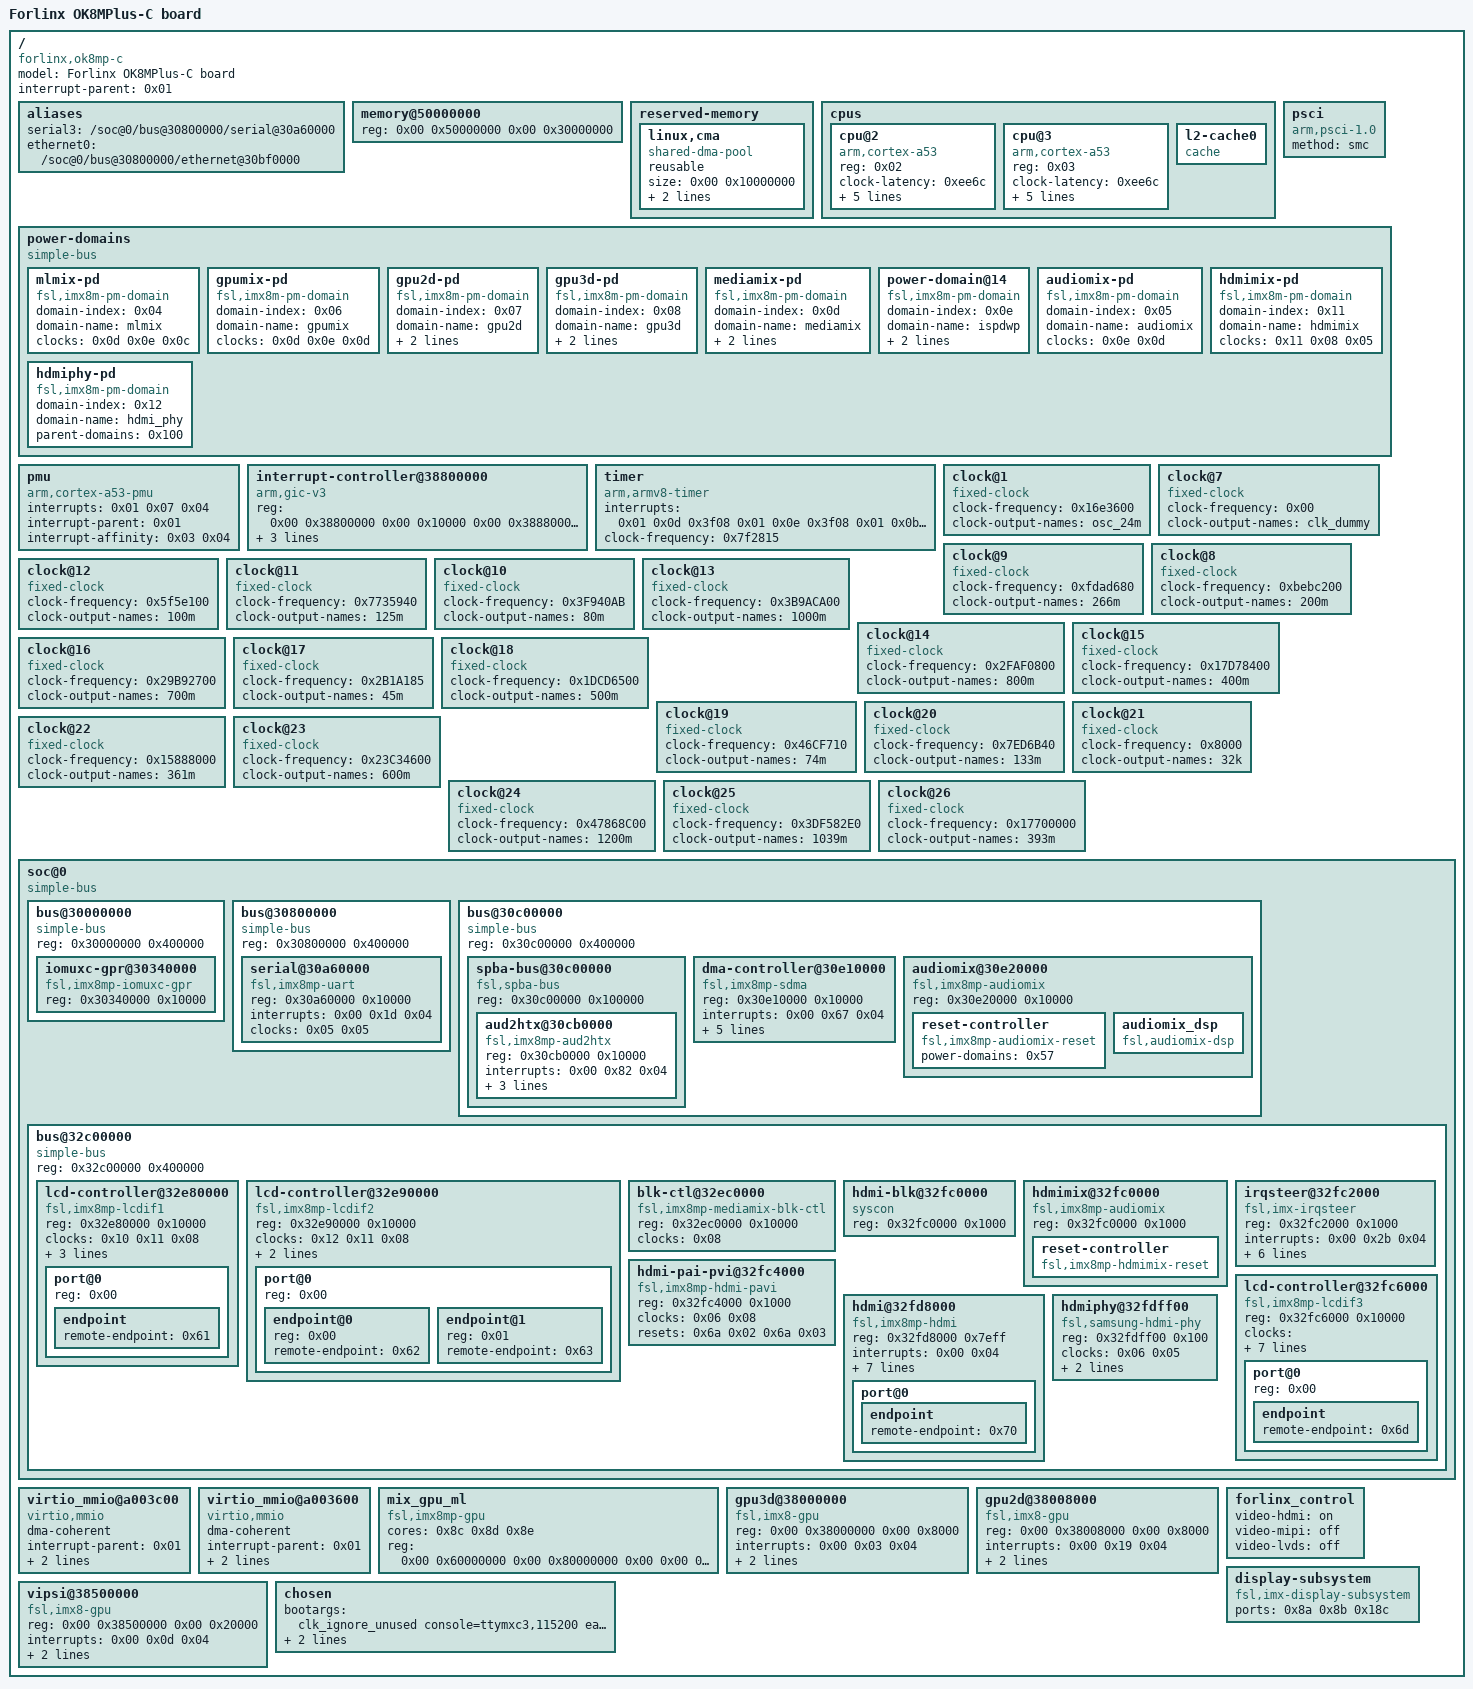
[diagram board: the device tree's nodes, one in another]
/dts-v1/;

/ {
	compatible = "forlinx,ok8mp-c\0fsl,imx8mp-evk\0fsl,/home/lgw/Documents/xwechat_files/wxid_ugo1mwfw18zq12_d8dd/msg/file/2024-07/linux2.json";
	model = "Forlinx OK8MPlus-C board";
	interrupt-parent = <0x01>;
	#address-cells = <0x02>;
	#size-cells = <0x02>;

	aliases {
		// serial1 = "/soc@0/bus@30800000/serial@30890000";
		serial3 = "/soc@0/bus@30800000/serial@30a60000";
	    // mmc3 = "/soc@0/bus@30800000/mmc@30b60000";
		ethernet0 = "/soc@0/bus@30800000/ethernet@30bf0000";
	};

	memory@50000000 {
		device_type = "memory";
		reg = <0x00 0x50000000 0x00 0x30000000>;
	};

	reserved-memory {
		#address-cells = <0x02>;
		#size-cells = <0x02>;
		ranges;

		linux,cma {
			compatible = "shared-dma-pool";
			reusable;
			size = <0x00 0x10000000>;
			alloc-ranges = <0x00 0x60000000 0x00 0x80000000>;
			linux,cma-default;
		};
	};

	cpus {
		#address-cells = <0x01>;
		#size-cells = <0x00>;
		// TODO: 增加idle-states for cpu
		// idle-states {
		// 	entry-method = "psci";

		// 	cpu-pd-wait {
		// 		// compatible = "arm,idle-state";
		// 		arm,psci-suspend-param = <0x10033>;
		// 		local-timer-stop;
		// 		entry-latency-us = <0x3e8>;
		// 		exit-latency-us = <0x2bc>;
		// 		min-residency-us = <0xa8c>;
		// 		wakeup-latency-us = <0x5dc>;
		// 		phandle = <0x06>;
		// 	};
		// };

		cpu@2 {
			device_type = "cpu";
			compatible = "arm,cortex-a53";
			reg = <0x02>;
			clock-latency = <0xee6c>;
			next-level-cache = <0x02>;
			clocks = <0x08>;
			operating-points-v2 = <0x04>;
			enable-method = "psci";
			#cooling-cells = <0x02>;
			cpu-idle-states = <0x06>;
			phandle = <0x103>;
		};

		cpu@3 {
			device_type = "cpu";
			compatible = "arm,cortex-a53";
			reg = <0x03>;
			clock-latency = <0xee6c>;
			next-level-cache = <0x02>;
			clocks = <0x08>;
			operating-points-v2 = <0x04>;
			enable-method = "psci";
			#cooling-cells = <0x02>;
			cpu-idle-states = <0x06>;
			phandle = <0x104>;
		};

		l2-cache0 {
			compatible = "cache";
			phandle = <0x02>;
		};
	};

	psci {
		compatible = "arm,psci-1.0";
		method = "smc";
	};

	
	power-domains {
		compatible = "simple-bus";

		mlmix-pd {
			compatible = "fsl,imx8m-pm-domain";
			#power-domain-cells = <0x00>;
			domain-index = <0x04>;
			domain-name = "mlmix";
			clocks = <0x0d 0x0e 0x0c>;
			phandle = <0x86>;
		};

		gpumix-pd {
			compatible = "fsl,imx8m-pm-domain";
			#power-domain-cells = <0x00>;
			domain-index = <0x06>;
			domain-name = "gpumix";
			clocks = <0x0d 0x0e 0x0d>;
			phandle = <0x7c>;
		};

		gpu2d-pd {
			compatible = "fsl,imx8m-pm-domain";
			#power-domain-cells = <0x00>;
			domain-index = <0x07>;
			domain-name = "gpu2d";
			parent-domains = <0x7c>;
			clocks = <0x0c>;
			phandle = <0x7e>;
		};

		gpu3d-pd {
			compatible = "fsl,imx8m-pm-domain";
			#power-domain-cells = <0x00>;
			domain-index = <0x08>;
			domain-name = "gpu3d";
			parent-domains = <0x7c>;
			clocks = <0x0c 0x0c>;
			phandle = <0x7d>;
		};

		mediamix-pd {
			compatible = "fsl,imx8m-pm-domain";
			#power-domain-cells = <0x00>;
			domain-index = <0x0d>;
			domain-name = "mediamix";
			rpm-always-on;
			clocks = <0x11 0x08>;
			phandle = <0x10f>;
		};

		power-domain@14 {
			compatible = "fsl,imx8m-pm-domain";
			#power-domain-cells = <0x00>;
			domain-index = <0x0e>;
			domain-name = "ispdwp";
			parent-domains = <0x10f>;
			clocks = <0x11>;
			phandle = <0x71>;
		};

		audiomix-pd {
			compatible = "fsl,imx8m-pm-domain";
			#power-domain-cells = <0x00>;
			domain-index = <0x05>;
			domain-name = "audiomix";
			clocks = <0x0e 0x0d>;
			phandle = <0x57>;
		};

		hdmimix-pd {
			compatible = "fsl,imx8m-pm-domain";
			#power-domain-cells = <0x00>;
			domain-index = <0x11>;
			domain-name = "hdmimix";
			clocks = <0x11 0x08 0x05>;
			// clocks = <0x116 0x63 0xa8>;
			phandle = <0x100>;
		};

		hdmiphy-pd {
			compatible = "fsl,imx8m-pm-domain";
			#power-domain-cells = <0x00>;
			domain-index = <0x12>;
			domain-name = "hdmi_phy";
			parent-domains = <0x100>;
			phandle = <0x6f>;
		};
	};

	pmu {
		compatible = "arm,cortex-a53-pmu";
		interrupts = <0x01 0x07 0x04>;
		interrupt-parent = <0x01>;
		interrupt-affinity = <0x03 0x04>;
	};

	interrupt-controller@38800000 {
		compatible = "arm,gic-v3";
		reg = <0x00 0x38800000 0x00 0x10000 0x00 0x38880000 0x00 0xc0000>;
		#interrupt-cells = <0x03>;
		interrupt-controller;
		interrupts = <0x01 0x09 0x04>;
		interrupt-parent = <0x01>;
		phandle = <0x01>;
	};

	timer {
		compatible = "arm,armv8-timer";
		interrupts = <0x01 0x0d 0x3f08 0x01 0x0e 0x3f08 0x01 0x0b 0x3f08 0x01 0x0a 0x3f08>;
		clock-frequency = <0x7f2815>;
	};

	clock@1 {
		compatible = "fixed-clock";
		#clock-cells = <0x00>;
		clock-frequency = <0x16e3600>;
		clock-output-names = "osc_24m";
		phandle = <0x05>;
	};


	clock@7 {
		compatible = "fixed-clock";
		#clock-cells = <0x00>;
		clock-frequency = <0x00>;
		clock-output-names = "clk_dummy";
		phandle = <0x06>;
	};

	clock@9 {
		compatible = "fixed-clock";
		#clock-cells = <0x00>;
		clock-frequency = <0xfdad680>;
		clock-output-names = "266m";
		phandle = <0x07>;
	};
	
	clock@8 {
		compatible = "fixed-clock";
		#clock-cells = <0x00>;
		clock-frequency = <0xbebc200>;
		clock-output-names = "200m";
		phandle = <0x08>;
	};

	clock@12 {
		compatible = "fixed-clock";
		#clock-cells = <0x00>;
		clock-frequency = <0x5f5e100>;
		clock-output-names = "100m";
		phandle = <0x09>;
	};

	clock@11 {
		compatible = "fixed-clock";
		#clock-cells = <0x00>;
		clock-frequency = <0x7735940>;
		clock-output-names = "125m";
		phandle = <0x0a>;
	};

	clock@10 {
		compatible = "fixed-clock";
		#clock-cells = <0x00>;
		clock-frequency = <0x3F940AB>;
		clock-output-names = "80m";
		phandle = <0x0b>;
	};

	clock@13 {
		compatible = "fixed-clock";
		#clock-cells = <0x00>;
		clock-frequency = <0x3B9ACA00>;
		clock-output-names = "1000m";
		phandle = <0x0c>;
	};
	
	clock@14 {
		compatible = "fixed-clock";
		#clock-cells = <0x00>;
		clock-frequency = <0x2FAF0800>;
		clock-output-names = "800m";
		phandle = <0x0d>;
	};

	clock@15 {
		compatible = "fixed-clock";
		#clock-cells = <0x00>;
		clock-frequency = <0x17D78400>;
		clock-output-names = "400m";
		phandle = <0x0e>;
	};

	clock@16 {
		compatible = "fixed-clock";
		#clock-cells = <0x00>;
		clock-frequency = <0x29B92700>;
		clock-output-names = "700m";
		phandle = <0x0f>;
	};

	clock@17 {
		compatible = "fixed-clock";
		#clock-cells = <0x00>;
		clock-frequency = <0x2B1A185>;
		clock-output-names = "45m";
		phandle = <0x10>;
	};

	clock@18 {
		compatible = "fixed-clock";
		#clock-cells = <0x00>;
		clock-frequency = <0x1DCD6500>;
		clock-output-names = "500m";
		phandle = <0x11>;
	};

	clock@19 {
		compatible = "fixed-clock";
		#clock-cells = <0x00>;
		clock-frequency = <0x46CF710>;
		clock-output-names = "74m";
		phandle = <0x12>;
	};

	clock@20 {
		compatible = "fixed-clock";
		#clock-cells = <0x00>;
		clock-frequency = <0x7ED6B40>;
		clock-output-names = "133m";
		phandle = <0x13>;
	};

	clock@21 {
		compatible = "fixed-clock";
		#clock-cells = <0x00>;
		clock-frequency = <0x8000>;
		clock-output-names = "32k";
		phandle = <0x14>;
	};

	clock@22 {
		compatible = "fixed-clock";
		#clock-cells = <0x00>;
		clock-frequency = <0x15888000>;
		clock-output-names = "361m";
		phandle = <0x15>;
	};

	clock@23 {
		compatible = "fixed-clock";
		#clock-cells = <0x00>;
		clock-frequency = <0x23C34600>;
		clock-output-names = "600m";
		phandle = <0x16>;
	};

	clock@24 {
		compatible = "fixed-clock";
		#clock-cells = <0x00>;
		clock-frequency = <0x47868C00>;
		clock-output-names = "1200m";
		phandle = <0x17>;
	};

	clock@25 {
		compatible = "fixed-clock";
		#clock-cells = <0x00>;
		clock-frequency = <0x3DF582E0>;
		clock-output-names = "1039m";
		phandle = <0x18>;
	};

	clock@26 {
		compatible = "fixed-clock";
		#clock-cells = <0x00>;
		clock-frequency = <0x17700000>;
		clock-output-names = "393m";
		phandle = <0x19>;
	};

	soc@0 {
		compatible = "simple-bus";
		#address-cells = <0x01>;
		#size-cells = <0x01>;
		ranges = <0x00 0x00 0x00 0x3e000000>;
		// dma-ranges = <0x40000000 0x00 0x40000000 0xc0000000>;

		bus@30000000 {
			compatible = "simple-bus";
			reg = <0x30000000 0x400000>;
			#address-cells = <0x01>;
			#size-cells = <0x01>;
			ranges;
			
			iomuxc-gpr@30340000 {
			 	compatible = "fsl,imx8mp-iomuxc-gpr\0fsl,imx7d-iomuxc-gpr\0fsl,imx6q-iomuxc-gpr\0syscon";
			 	reg = <0x30340000 0x10000>;
			 	phandle = <0x29>;
			};
		};

		bus@30800000 {
			compatible = "simple-bus";
			#address-cells = <0x01>;
			#size-cells = <0x01>;
			reg = <0x30800000 0x400000>;
			ranges;

			// serial@30890000 {
			// 	compatible = "fsl,imx8mq-uart\0fsl,imx6q-uart";
			// 	reg = <0x30890000 0x10000>;
			// 	interrupts = <0x00 0x1b 0x04>;
			// 	status = "okay";
			// 	clocks = <0x05 0x05>;
			// 	clock-names = "ipg\0per";
			// };

			serial@30a60000 {
				compatible = "fsl,imx8mp-uart\0fsl,imx6q-uart";
				reg = <0x30a60000 0x10000>;
				interrupts = <0x00 0x1d 0x04>;
				clocks = <0x05 0x05>;
				clock-names = "ipg\0per";
				status = "okay";
				// dmas = <0x22 0x1c 0x04 0x00 0x22 0x1d 0x04 0x00>;
				// dma-names = "rx\0tx";
				// status = "disabled";
			};
			// sd card
			// mmc@30b50000 {
			// 	compatible = "fsl,imx8mm-usdhc\0fsl,imx7d-usdhc";
			// 	reg = <0x30b50000 0x10000>;
			// 	interrupts = <0x00 0x17 0x04>;
			// 	clocks = <0x06 0x07 0x08>;
			// 	clock-names = "ipg\0ahb\0per";
			// 	fsl,tuning-start-tap = <0x14>;
			// 	fsl,tuning-step = <0x02>;
			// 	bus-width = <0x04>;
			// 	status = "okay";
			// };
			// emmc
			// mmc@30b60000 {
			// 	compatible = "fsl,imx8mm-usdhc\0fsl,imx7d-usdhc";
			// 	reg = <0x30b60000 0x10000>;
			// 	interrupts = <0x00 0x18 0x04>;
			// 	fsl,tuning-start-tap = <0x14>;
			// 	fsl,tuning-step = <0x02>;
			// 	status = "okay";
			// 	clocks = <0x06 0x07 0x08>;
			// 	clock-names = "ipg\0ahb\0per";
			// 	bus-width = <0x08>;
			// 	non-removable;
			// };


			// ethernet@30bf0000 {
			// 	compatible = "nxp,imx8mp-dwmac-eqos\0snps,dwmac-5.10a";
			// 	reg = <0x30bf0000 0x10000>;
			// 	interrupts = <0x00 0x86 0x04 0x00 0x87 0x04>;
			// 	interrupt-names = "eth_wake_irq\0macirq";
			// 	clocks = <0x07 0x0b 0x09 0x0a>;
			// 	clock-names = "stmmaceth\0pclk\0ptp_ref\0tx";
			// 	// assigned-clocks = <0x03 0x5e 0x03 0x82 0x03 0x81>;
			// 	// assigned-clock-parents = <0x03 0x36 0x03 0x3a 0x03 0x3b>;
			// 	// assigned-clock-rates = <0x00 0x5f5e100 0x7735940>;
			// 	// nvmem-cells = <0x52>;
			// 	// nvmem-cell-names = "mac-address";
			// 	// nvmem_macaddr_swap;
			// 	intf_mode = <0x29 0x04>;
			// 	status = "okay";
			// 	// pinctrl-names = "default";
			// 	// pinctrl-0 = <0x53>;
			// 	reset-gpio = <0x25 0x05 0x01>;
			// 	phy-mode = "rgmii-id";
			// 	phy-handle = <0x54>;

			// 	mdio {
			// 		compatible = "snps,dwmac-mdio";
			// 		#address-cells = <0x01>;
			// 		#size-cells = <0x00>;

			// 		ethernet-phy@1 {
			// 			compatible = "ethernet-phy-ieee802.3-c22";
			// 			reg = <0x01>;
			// 			eee-broken-1000t;
			// 			at803x,vddio-1p8v;
			// 			at803x,hibernate-disable;
			// 			phandle = <0x54>;
			// 		};
			// 	};
			// };
		};

		// hdmi
		bus@30c00000 {
			compatible = "simple-bus";
			reg = <0x30c00000 0x400000>;
			#address-cells = <0x01>;
			#size-cells = <0x01>;
			ranges;
		
			spba-bus@30c00000 {
				compatible = "fsl,spba-bus\0simple-bus";
				reg = <0x30c00000 0x100000>;
				#address-cells = <0x01>;
				#size-cells = <0x01>;
				ranges;
			
				aud2htx@30cb0000 {
					compatible = "fsl,imx8mp-aud2htx";
					reg = <0x30cb0000 0x10000>;
					interrupts = <0x00 0x82 0x04>;
					clocks = <0x0e>;
					clock-names = "bus";
					dmas = <0x56 0x1a 0x02 0x00>;
					dma-names = "tx";
					power-domains = <0x57>;
					status = "okay";
					phandle = <0xa6>;
				};
			};
		
			dma-controller@30e10000 {
				compatible = "fsl,imx8mp-sdma\0fsl,imx7d-sdma";
				reg = <0x30e10000 0x10000>;
				interrupts = <0x00 0x67 0x04>;
				clocks = <0x0e 0x0e>;
				clock-names = "ipg\0ahb";
				#dma-cells = <0x03>;
				fsl,sdma-ram-script-name = "imx/sdma/sdma-imx7d.bin";
				fsl,ratio-1-1;
				power-domains = <0x57>;
				status = "okay";
				phandle = <0x56>;
			};


			audiomix@30e20000 {
				compatible = "fsl,imx8mp-audiomix";
				reg = <0x30e20000 0x10000>;

				// clock-controller {
				// 	compatible = "fsl,imx8mp-audiomix-clk";
				// 	#clock-cells = <0x01>;
				// 	clocks = <0x0e>;
				// 	clock-names = "audio_root";
				// 	power-domains = <0x57>;
				// 	phandle = <0x3c>;
				// };

				reset-controller {
					compatible = "fsl,imx8mp-audiomix-reset";
					power-domains = <0x57>;
					#reset-cells = <0x01>;
					phandle = <0x5a>;
				};

				audiomix_dsp {
					compatible = "fsl,audiomix-dsp";
				};
			};
		};
		// hdmi
		bus@32c00000 {
			compatible = "simple-bus";
			reg = <0x32c00000 0x400000>;
			#address-cells = <0x01>;
			#size-cells = <0x01>;
			ranges;

			lcd-controller@32e80000 {
				#address-cells = <0x01>;
				#size-cells = <0x00>;
				compatible = "fsl,imx8mp-lcdif1";
				reg = <0x32e80000 0x10000>;
				clocks = <0x10 0x11 0x08>;
				clock-names = "pix\0disp-axi\0disp-apb";
				// assigned-clocks = <0x03 0xac 0x03 0x61 0x03 0x62>;
				// assigned-clock-parents = <0x03 0x28 0x03 0x41 0x03 0x38>;
				// assigned-clock-rates = <0x00 0x1dcd6500 0xbebc200>;
				interrupts = <0x00 0x05 0x04>;
				blk-ctl = <0x5c>;
				power-domains = <0x10f>;
				status = "okay";

				port@0 {
					reg = <0x00>;
					phandle = <0x8a>;

					endpoint {
						remote-endpoint = <0x61>;
						phandle = <0x5d>;
					};
				};
			};

			lcd-controller@32e90000 {
				#address-cells = <0x01>;
				#size-cells = <0x00>;
				compatible = "fsl,imx8mp-lcdif2";
				reg = <0x32e90000 0x10000>;
				clocks = <0x12 0x11 0x08>;
				clock-names = "pix\0disp-axi\0disp-apb";
				// assigned-clocks = <0x03 0x121 0x03 0x61 0x03 0x62>;
				// assigned-clock-parents = <0x03 0x28 0x03 0x41 0x03 0x38>;
				// assigned-clock-rates = <0x00 0x1dcd6500 0xbebc200>;
				interrupts = <0x00 0x06 0x04>;
				power-domains = <0x10f>;
				status = "okay";

				port@0 {
					#address-cells = <0x01>;
					#size-cells = <0x00>;
					reg = <0x00>;
					phandle = <0x8b>;

					endpoint@0 {
						reg = <0x00>;
						remote-endpoint = <0x62>;
						phandle = <0x65>;
					};

					endpoint@1 {
						reg = <0x01>;
						remote-endpoint = <0x63>;
						phandle = <0x68>;
					};
				};
			};

			blk-ctl@32ec0000 {
				compatible = "fsl,imx8mp-mediamix-blk-ctl\0syscon";
				reg = <0x32ec0000 0x10000>;
				clocks = <0x08>;
				phandle = <0x5c>;
			};
			
			hdmi-blk@32fc0000 {
				compatible = "syscon";
				reg = <0x32fc0000 0x1000>;
				phandle = <0x6e>;
			};

			hdmimix@32fc0000 {
				compatible = "fsl,imx8mp-audiomix\0fsl,imx8mp-hdmimix";
				reg = <0x32fc0000 0x1000>;

				// clock-controller {
				// 	compatible = "fsl,imx8mp-hdmimix-clk";
				// 	#clock-cells = <0x01>;
				// 	clocks = <0x06>;
				// 	clock-names = "dummy";
				// 	status = "okay";
				// 	phandle = <0x69>;
				// };

				reset-controller {
					compatible = "fsl,imx8mp-hdmimix-reset";
					#reset-cells = <0x01>;
					status = "okay";
					phandle = <0x6a>;
				};
			};
			// hdmi 用到的中断控制器
			irqsteer@32fc2000 {
				compatible = "fsl,imx-irqsteer";
				reg = <0x32fc2000 0x1000>;
				interrupts = <0x00 0x2b 0x04>;
				interrupt-controller;
				interrupt-parent = <0x01>;
				#interrupt-cells = <0x01>;
				fsl,channel = <0x01>;
				fsl,num-irqs = <0x40>;
				clocks = <0x08>;
				clock-names = "ipg";
				// assigned-clocks = <0x03 0x63>;
				// assigned-clock-parents = <0x03 0x38>;
				// assigned-clock-rates = <0xbebc200>;
				resets = <0x6a 0x05>;
				status = "okay";
				phandle = <0x6c>;
			};

			hdmi-pai-pvi@32fc4000 {
				compatible = "fsl,imx8mp-hdmi-pavi";
				reg = <0x32fc4000 0x1000>;
				clocks = <0x06 0x08>;
				clock-names = "pvi_clk\0pai_clk";
				resets = <0x6a 0x02 0x6a 0x03>;
				reset-names = "pai_rst\0pvi_rst";
				status = "okay";
			};

			lcd-controller@32fc6000 {
				#address-cells = <0x01>;
				#size-cells = <0x00>;
				compatible = "fsl,imx8mp-lcdif3";
				reg = <0x32fc6000 0x10000>;
				// clocks = <0x6b 0x00 0x03 0x64 0x03 0x63 0x69 0x00 0x69 0x01 0x69 0x03 0x69 0x05 0x69 0x09 0x69 0x0a 0x69 0x0b 0x69 0x0c 0x69 0x0d 0x69 0x07>;
				clocks = <0x06 0x11 0x08 0x08 0x11 0x05 0x06 0x08 0x11 0x08 0x06 0x08 0x08>;
				clock-names = "pix\0disp-axi\0disp-apb\0mix_apb\0mix_axi\0xtl_24m\0mix_pix\0lcdif_apb\0lcdif_axi\0lcdif_pdi\0lcdif_pix\0lcdif_spu\0noc_hdmi";
				// assigned-clocks = <0x03 0x64 0x03 0x63>;
				// assigned-clock-parents = <0x03 0x40 0x03 0x38>;
				// assigned-clock-rates = <0x1dcd6500 0xbebc200>;
				interrupts = <0x08 0x04>;
				interrupt-parent = <0x6c>;
				resets = <0x6a 0x07>;
				power-domains = <0x100>;
				status = "okay";
				thres-low = <0x01 0x02>;
				thres-high = <0x03 0x04>;

				port@0 {
					reg = <0x00>;
					phandle = <0x18c>;

					endpoint {
						remote-endpoint = <0x6d>;
						phandle = <0x70>;
					};
				};
			};

			hdmi@32fd8000 {
				compatible = "fsl,imx8mp-hdmi";
				reg = <0x32fd8000 0x7eff>;
				// 0x00表示它连到中断控制器的第0个引脚，该中断控制器是irqsteer，它连到GIC中断线代表32+0x2b号中断。因此hdmi发出中断，CPU收到的就是32+0x2b
				interrupts = <0x00 0x04>; 
				interrupt-parent = <0x6c>;
				clocks = <0x08 0x05 0x08 0x08 0x08 0x08 0x06 0x14 0x08 0x08 0x05 0x06>;
				clock-names = "iahb\0isfr\0phy_int\0prep_clk\0skp_clk\0sfr_clk\0pix_clk\0cec_clk\0apb_clk\0hpi_clk\0fdcc_ref\0pipe_clk";
				// assigned-clocks = <0x03 0x63 0x03 0x64 0x03 0xa7>;
				// assigned-clock-parents = <0x03 0x38 0x03 0x40 0x03 0x02>;
				// assigned-clock-rates = <0xbebc200 0x1dcd6500 0x16e3600>;
				phys = <0x6b>;
				phy-names = "hdmi";
				resets = <0x6a 0x00>;
				gpr = <0x6e>;
				power-domains = <0x6f>;
				status = "okay";

				port@0 {

					endpoint {
						remote-endpoint = <0x70>;
						phandle = <0x6d>;
					};
				};
			};

			hdmiphy@32fdff00 {
				compatible = "fsl,samsung-hdmi-phy";
				reg = <0x32fdff00 0x100>;
				#clock-cells = <0x01>;
				clocks = <0x06 0x05>;
				clock-names = "apb\0ref";
				clock-output-names = "hdmi_phy";
				#phy-cells = <0x00>;
				resets = <0x6a 0x01>;
				status = "okay";
				phandle = <0x6b>;
			};
		};
	};
	// virtio blk
	virtio_mmio@a003c00 {
		dma-coherent;
		interrupt-parent = <0x01>;
		interrupts = <0x0 0x2e 0x1>;
		reg = <0x0 0xa003c00 0x0 0x200>;
		compatible = "virtio,mmio";
	};
	// virtio net
	virtio_mmio@a003600 {
		dma-coherent;
		interrupt-parent = <0x01>;
		interrupts = <0x0 0x2b 0x1>;
		reg = <0x0 0xa003600 0x0 0x200>;
		compatible = "virtio,mmio";
	};

	// virtio serial
	// virtio_mmio@a003800 {
	// 	dma-coherent;
	// 	interrupt-parent = <0x01>;
	// 	interrupts = <0x0 0x2c 0x1>;
	// 	reg = <0x0 0xa003800 0x0 0x200>;
	// 	compatible = "virtio,mmio";
	// };

	mix_gpu_ml {
		compatible = "fsl,imx8mp-gpu\0fsl,imx8-gpu-ss";
		cores = <0x8c 0x8d 0x8e>;
		reg = <0x00 0x60000000 0x00 0x80000000 0x00 0x00 0x00 0x10000000>;
		reg-names = "phys_baseaddr\0contiguous_mem";
		status = "okay";
	};

	gpu3d@38000000 {
		compatible = "fsl,imx8-gpu";
		reg = <0x00 0x38000000 0x00 0x8000>;
		interrupts = <0x00 0x03 0x04>;
		clocks = <0x0c 0x0c 0x0d 0x0e>;
		clock-names = "core\0shader\0axi\0ahb";
		// to be config:
		// assigned-clocks = <0x03 0x45 0x03 0x46 0x03 0x65 0x03 0x66>;
		// assigned-clock-parents = <0x03 0x41 0x03 0x41 0x03 0x38 0x03 0x38>;
		// assigned-clock-rates = <0x3b9aca00 0x3b9aca00 0x2faf0800 0x17d78400>;
		power-domains = <0x7d>;
		status = "okay";
		phandle = <0x8c>;
	};
	
	gpu2d@38008000 {
		compatible = "fsl,imx8-gpu";
		reg = <0x00 0x38008000 0x00 0x8000>;
		interrupts = <0x00 0x19 0x04>;
		clocks = <0x0c 0x0d 0x0e>;
		clock-names = "core\0axi\0ahb";
		// assigned-clocks = <0x03 0x47 0x03 0x65 0x03 0x66>;
		// assigned-clock-parents = <0x03 0x41 0x03 0x38 0x03 0x38>;
		// assigned-clock-rates = <0x3b9aca00 0x2faf0800 0x17d78400>;
		power-domains = <0x7e>;
		status = "okay";
		phandle = <0x8e>;
	};

	vipsi@38500000 {
		compatible = "fsl,imx8-gpu\0fsl,imx8-vipsi";
		reg = <0x00 0x38500000 0x00 0x20000>;
		interrupts = <0x00 0x0d 0x04>;
		clocks = <0x0c 0x0c 0x0d 0x0e>;
		clock-names = "core\0shader\0axi\0ahb";
		// assigned-clocks = <0x03 0x44 0x03 0x69 0x03 0x6a>;
		// assigned-clock-parents = <0x03 0x41 0x03 0x38 0x03 0x38>;
		// assigned-clock-rates = <0x3b9aca00 0x2faf0800 0x17d78400>;
		power-domains = <0x86>;
		status = "okay";
		phandle = <0x8d>;
	};

	forlinx_control {
		status = "okay";
		video-hdmi = "on";
		video-mipi = "off";
		video-lvds = "off";
	};

	display-subsystem {
		compatible = "fsl,imx-display-subsystem";
		ports = <0x8a 0x8b 0x18c>;
	};

	chosen {
		// real blk and real console:
		// bootargs = "clk_ignore_unused console=ttymxc3,115200 earlycon=ec_imx6q3,0x30a60000,115200 root=/dev/mmcblk3p2 rootwait rw";
		// stdout-path = "/soc@0/bus@30800000/serial@30a60000";

		// virtio blk and real console:
		bootargs = "clk_ignore_unused console=ttymxc3,115200 earlycon=ec_imx6q3,0x30a60000,115200 root=/dev/vda rootwait rw";
		stdout-path = "/soc@0/bus@30800000/serial@30a60000";

		// virtio blk and virtio console:
		// bootargs = "clk_ignore_unused earlycon=virtio,mmio,0xa003800 console=hvc0 root=/dev/vda rootwait rw";
		// stdout-path = "/virtio_mmio@a003800";
	};
};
